# FM33FK5XX register map
File version: 1.0
CPU: Cortex-M33 r1p0, little endian, MPU, FPU, 3 interrupt priority bits
Registers are 32-bit, read-write, reset 0x0 unless marked. A register's access mark holds for its fields unless they carry their own. Offsets are from the block's base; [hi:lo] are bit positions.

## SFU — SFU module information
Base 0x40002C00
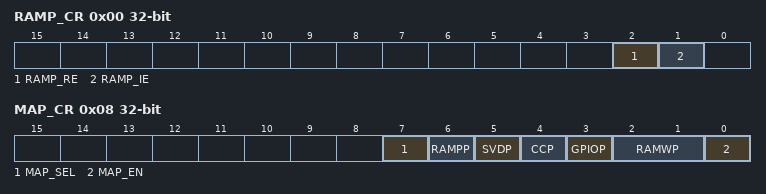
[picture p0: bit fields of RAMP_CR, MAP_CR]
0x00 RAMP_CR — RAMParityControlRegister
  [2] RAMP_RE — RAMP_RE field description
  [1] RAMP_IE — RAMP_IE field description
0x08 MAP_CR — MemoryAccessProtectionControlRegister
  [7] MAP_SEL — MAP_SEL field description
  [6] RAMPP — RAMPP field description
  [5] SVDP — SVDP field description
  [4] CCP — CCP field description
  [3] GPIOP — GPIOP field description
  [2:1] RAMWP — RAMWP field description
  [0] MAP_EN — MAP_EN field description
0x0C MAP_SR — MemoryAccessProtectionControlRegister
  [0] MAP_IF — MAP_IF field description

## QSPI — QSPI module information
Base 0xE0044000
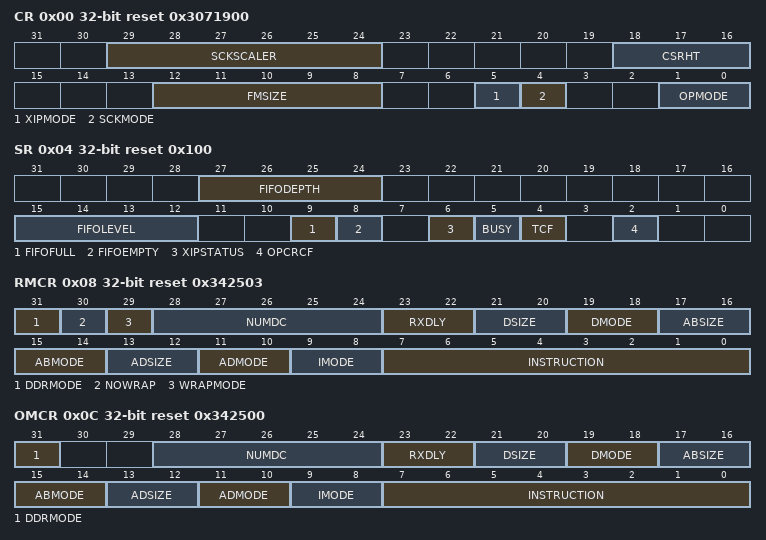
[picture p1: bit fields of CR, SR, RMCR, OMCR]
0x00 CR reset 0x3071900
  [29:24] SCKSCALER — SCKSCALER field description
  [18:16] CSRHT — CSRHT field description
  [12:8] FMSIZE — FMSIZE field description
  [5] XIPMODE — XIPMODE field description
  [4] SCKMODE — SCKMODE field description
  [1:0] OPMODE — OPMODE field description
0x04 SR access per field reset 0x100
  [27:24] FIFODEPTH ro — FIFODEPTH field description
  [15:12] FIFOLEVEL ro — FIFOLEVEL field description
  [9] FIFOFULL rw — FIFOFULL field description
  [8] FIFOEMPTY rw — FIFOEMPTY field description
  [6] XIPSTATUS ro — XIPSTATUS field description
  [5] BUSY ro — BUSY field description
  [4] TCF rw — TCF field description
  [2] OPCRCF ro — OPCRCF field description
0x08 RMCR reset 0x342503
  [31] DDRMODE — DDRMODE field description
  [30] NOWRAP — NOWRAP field description
  [29] WRAPMODE — WRAPMODE field description
  [28:24] NUMDC — NUMDC field description
  [23:22] RXDLY — RXDLY field description
  [21:20] DSIZE — DSIZE field description
  [19:18] DMODE — DMODE field description
  [17:16] ABSIZE — ABSIZE field description
  [15:14] ABMODE — ABMODE field description
  [13:12] ADSIZE — ADSIZE field description
  [11:10] ADMODE — ADMODE field description
  [9:8] IMODE — IMODE field description
  [7:0] INSTRUCTION — INSTRUCTION field description
0x0C OMCR reset 0x342500
  [31] DDRMODE — DDRMODE field description
  [28:24] NUMDC — NUMDC field description
  [23:22] RXDLY — RXDLY field description
  [21:20] DSIZE — DSIZE field description
  [19:18] DMODE — DMODE field description
  [17:16] ABSIZE — ABSIZE field description
  [15:14] ABMODE — ABMODE field description
  [13:12] ADSIZE — ADSIZE field description
  [11:10] ADMODE — ADMODE field description
  [9:8] IMODE — IMODE field description
  [7:0] INSTRUCTION — INSTRUCTION field description
0x10 RABR
  [31:0] ALT — ALT field description
0x14 OABR
  [31:0] IMADDR — IMADDR field description
0x18 IMAR
  [31:0] FIFODATA — FIFODATA field description
0x1C FDR
  [31:0] IMADDR — IMADDR field description
0x20 DLR
  [19:0] DL — DL field description
0x24 WCNT
  [29:0] WCNT — WCNT field description

## SCU — SCU module information
Base 0x40000000
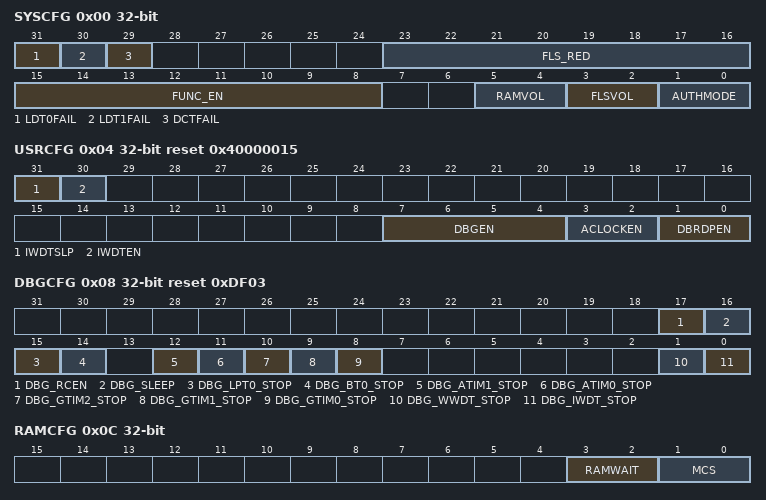
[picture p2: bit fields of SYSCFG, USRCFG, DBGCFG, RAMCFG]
0x00 SYSCFG ro
  [31] LDT0FAIL — LDT0FAIL field description
  [30] LDT1FAIL — LDT1FAIL field description
  [29] DCTFAIL — DCTFAIL field description
  [23:16] FLS_RED — FLS_RED field description
  [15:8] FUNC_EN — FUNC_EN field description
  [5:4] RAMVOL — RAMVOL field description
  [3:2] FLSVOL — FLSVOL field description
  [1:0] AUTHMODE — AUTHMODE field description
0x04 USRCFG ro reset 0x40000015
  [31] IWDTSLP — IWDTSLP field description
  [30] IWDTEN — IWDTEN field description
  [7:4] DBGEN — DBGEN field description
  [3:2] ACLOCKEN — ACLOCKEN field description
  [1:0] DBRDPEN — DBRDPEN field description
0x08 DBGCFG reset 0xDF03
  [17] DBG_RCEN — DBG_RCEN field description
  [16] DBG_SLEEP — DBG_SLEEP field description
  [15] DBG_LPT0_STOP — DBG_LPT0_STOP field description
  [14] DBG_BT0_STOP — DBG_BT0_STOP field description
  [12] DBG_ATIM1_STOP — DBG_ATIM1_STOP field description
  [11] DBG_ATIM0_STOP — DBG_ATIM0_STOP field description
  [10] DBG_GTIM2_STOP — DBG_GTIM2_STOP field description
  [9] DBG_GTIM1_STOP — DBG_GTIM1_STOP field description
  [8] DBG_GTIM0_STOP — DBG_GTIM0_STOP field description
  [1] DBG_WWDT_STOP — DBG_WWDT_STOP field description
  [0] DBG_IWDT_STOP — DBG_IWDT_STOP field description
0x0C RAMCFG
  [3:2] RAMWAIT — RAMWAIT field description
  [1:0] MCS — MCS field description
0x10 FLS_ACLOCK1 reset 0xFFFFFFFF
  [31:0] LOCK1 — LOCK1 field description
0x14 FLS_ACLOCK2 reset 0xFFFFFFFF
  [31:0] LOCK2 — LOCK2 field description
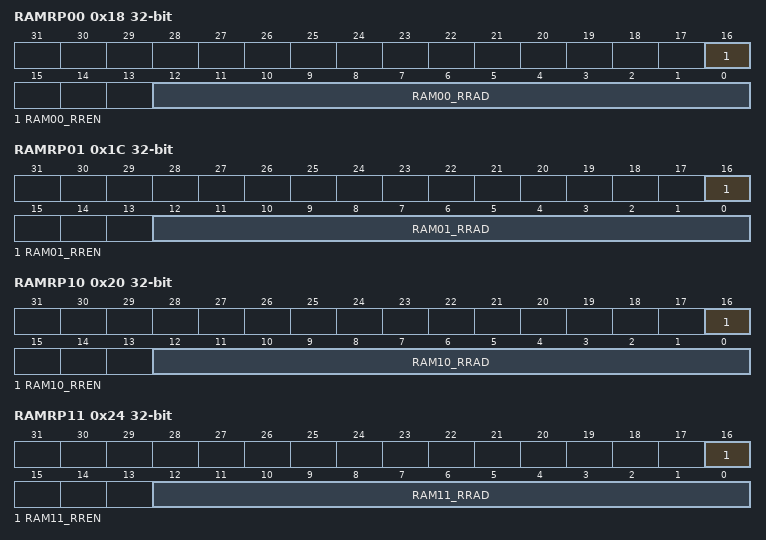
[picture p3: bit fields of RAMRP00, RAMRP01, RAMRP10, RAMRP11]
0x18 RAMRP00 ro
  [16] RAM00_RREN — RAM00_RREN field description
  [12:0] RAM00_RRAD — RAM00_RRAD field description
0x1C RAMRP01 ro
  [16] RAM01_RREN — RAM01_RREN field description
  [12:0] RAM01_RRAD — RAM01_RRAD field description
0x20 RAMRP10 ro
  [16] RAM10_RREN — RAM10_RREN field description
  [12:0] RAM10_RRAD — RAM10_RRAD field description
0x24 RAMRP11 ro
  [16] RAM11_RREN — RAM11_RREN field description
  [12:0] RAM11_RRAD — RAM11_RRAD field description
0x2C FLS_TSTEN ro
  [7:0] FLS_TSTEN — FLS_TSTEN field description
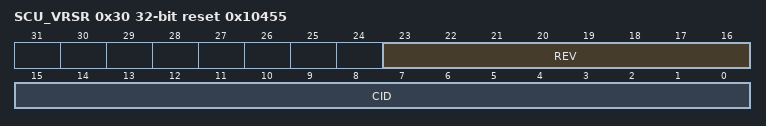
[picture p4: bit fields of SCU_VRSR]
0x30 SCU_VRSR ro reset 0x10455
  [23:16] REV — REV field description
  [15:0] CID — CID field description
0x34 FLS_DCT0 ro
  [31:0] FLSDCT0 — FLSDCT0 field description
0x38 FLS_DCT1 ro
  [31:0] FLSDCT1 — FLSDCT1 field description
